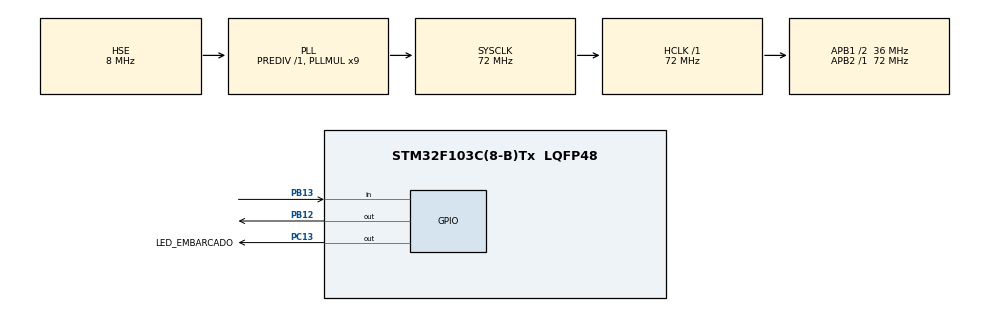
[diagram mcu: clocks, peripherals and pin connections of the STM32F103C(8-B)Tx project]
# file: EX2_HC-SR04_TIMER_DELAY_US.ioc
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Mcu.Family=STM32F1
Mcu.Name=STM32F103C(8-B)Tx
Mcu.Package=LQFP48
NVIC.PriorityGroup=NVIC_PRIORITYGROUP_4
PA13.Mode=Serial_Wire
PA13.Signal=SYS_JTMS-SWDIO
PA14.Mode=Serial_Wire
PA14.Signal=SYS_JTCK-SWCLK
PB12.Signal=GPIO_Output
PB13.Signal=GPIO_Input
PC13-TAMPER-RTC.GPIO_Label=LED_EMBARCADO
PC13-TAMPER-RTC.Signal=GPIO_Output
PD0-OSC_IN.Mode=HSE-External-Oscillator
PD0-OSC_IN.Signal=RCC_OSC_IN
PD1-OSC_OUT.Mode=HSE-External-Oscillator
PD1-OSC_OUT.Signal=RCC_OSC_OUT
ProjectManager.HeapSize=0x200
ProjectManager.StackSize=0x400
ProjectManager.TargetToolchain=STM32CubeIDE
RCC.AHBFreq_Value=72000000
RCC.APB1CLKDivider=RCC_HCLK_DIV2
RCC.APB1Freq_Value=36000000
RCC.APB1TimFreq_Value=72000000
RCC.APB2Freq_Value=72000000
RCC.APB2TimFreq_Value=72000000
RCC.HCLKFreq_Value=72000000
RCC.PLLMUL=RCC_PLL_MUL9
RCC.PLLSourceVirtual=RCC_PLLSOURCE_HSE
RCC.SYSCLKFreq_VALUE=72000000
RCC.SYSCLKSource=RCC_SYSCLKSOURCE_PLLCLK
RCC.USBFreq_Value=72000000
TIM1.Period=0xffff-1
TIM1.Prescaler=72-1
VP_TIM1_VS_ClockSourceINT.Mode=Internal
board=custom

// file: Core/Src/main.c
/* USER CODE BEGIN Header */
/**
  ******************************************************************************
  * @file           : main.c
  * @brief          : Main program body
  ******************************************************************************
  *						 EXEMPLO DE SENSOR ULTRASSOM (stm32f103c8)
  ******************************************************************************
  * Aluno:        Ruan Robert Bispo dos Santos                            2019.2
  * Orientadores: Lucas Molina e Elyson Adan Nunes Carvalho
  *
  * CODIGO DA PLACA DE INTERFACE DO MATLAB COM O STM32F103C8
  *
  * @Resumo: Código teste para sensor ultrassom HC-SR04. Nesse exemplo é
  * 		 implementada uma função delay_us que usa o timer para fazer o delay
  * 		 em micro segundos, assim atuando no sensor ultrassônico.O
  *
  * @Configurações:
  *   		 Clock   - 72 MHz
  *
  * @Funções:
  * 		 void delay_us (uint16_t us)
  * 		 uint32_t hcsr04_read (void)
  *
  *
  ******************************************************************************* @attention
  *
  * <h2><center>&copy; Copyright (c) 2020 STMicroelectronics.
  * All rights reserved.</center></h2>
  *
  * This software component is licensed by ST under BSD 3-Clause license,
  * the "License"; You may not use this file except in compliance with the
  * License. You may obtain a copy of the License at:
  *                        opensource.org/licenses/BSD-3-Clause
  *
  ******************************************************************************
  */
/* USER CODE END Header */

#include "main.h"

/* USER CODE BEGIN PD */

#define Trig_Pin  GPIO_PIN_12       //Pino usado para trigger (definir como pino de saída/gravação)
#define Trig_Port GPIOB			    //Port utilizado no pino de Trigger
#define Echo_Pin  GPIO_PIN_13		//Pino usado para eco (definir como pino de entrada/leitura)
#define Echo_Port GPIOB				//Port utilizado no pino de eco

/* USER CODE END PD */

TIM_HandleTypeDef htim1;

/* USER CODE BEGIN PV */

uint32_t tempo_local;
uint32_t tempo_sensor;
uint32_t distancia;

/* USER CODE END PV */

void SystemClock_Config(void);
static void MX_GPIO_Init(void);
static void MX_TIM1_Init(void);
/* USER CODE BEGIN PFP */

////////////////////////////////////////////////////////
////////////// FUNÇÕES PARA ULTRASSOM //////////////////
////////////////////////////////////////////////////////

// função delay em micro segundos
void delay_us (uint16_t us) // É necessário antes configurar o timer para 1MHz
{
	__HAL_TIM_SET_COUNTER(&htim1,0);  // set o contador como zero
	while (__HAL_TIM_GET_COUNTER(&htim1) < us);  // espera até o contador alcançar o tempo
}

// read ultrassom
uint32_t hcsr04_read (void)
{
	tempo_local=0;
	HAL_GPIO_WritePin(Trig_Port, Trig_Pin, GPIO_PIN_RESET);  // Coloca o trigger em nível alto
	delay_us(2);  											 // Espera 2 us

	HAL_GPIO_WritePin(Trig_Port, Trig_Pin, GPIO_PIN_SET);    // Coloca o trigger em nível alto
	delay_us(10); 											 // Espera 10 us
	HAL_GPIO_WritePin(Trig_Port, Trig_Pin, GPIO_PIN_RESET);  // Coloca o trigger em nível baixo

	// Lê o tempo que o pino passou em alto

	while (!(HAL_GPIO_ReadPin(Echo_Port, Echo_Pin)));  		// Espera o pino de eco ficar em alto
	while (HAL_GPIO_ReadPin(Echo_Port, Echo_Pin)) 		    // Preso enquanto o pino está em alto
	 {
		tempo_local++;   									// Mede o tempo que ficou em alto
		delay_us(1);
	 }
	return tempo_local;										// Retorna o tempo
}

/* USER CODE END PFP */

int main(void)
{
  /* USER CODE BEGIN 1 */

	///////////////////////////////////////////////////////////////////
	/////////////////// INICIALIZAÇÃO DE FUNÇÕES //////////////////////
	///////////////////////////////////////////////////////////////////

	// timer (ultrassom)
	HAL_TIM_Base_Start(&htim1);
	__HAL_TIM_SET_COUNTER(&htim1,0);  // set the counter value a 0

	///////////////////////////////////////////////////////////////////
	///////////////////////////////////////////////////////////////////

  /* USER CODE END 1 */

  /* MCU Configuration--------------------------------------------------------*/

  /* Reset of all peripherals, Initializes the Flash interface and the Systick. */
  HAL_Init();

  /* Configure the system clock */
  SystemClock_Config();

  /* Initialize all configured peripherals */
  MX_GPIO_Init();
  MX_TIM1_Init();

  /* Infinite loop */
  /* USER CODE BEGIN WHILE */
  while (1)
  {

	  // ULTRASSOM *****************************************//
	  	  tempo_sensor = hcsr04_read();    			 // tempo de leitura até o sinal retornar
	  	  distancia  = tempo_sensor * 0.034;			 // usa velocidade do som para calcular a distancia
	  // ***************************************************//

	  // Indicador de que o código está sendo executado (Piscar LED)
		  HAL_GPIO_TogglePin(GPIOC, GPIO_PIN_13); 	 //Pisca led da placa
		  HAL_Delay(500);   						 //Delay em milisegundos

    /* USER CODE END WHILE */

  }
}

void SystemClock_Config(void)
{
  RCC_OscInitTypeDef RCC_OscInitStruct = {0};
  RCC_ClkInitTypeDef RCC_ClkInitStruct = {0};

  /** Initializes the CPU, AHB and APB busses clocks
  */
  RCC_OscInitStruct.OscillatorType = RCC_OSCILLATORTYPE_HSE;
  RCC_OscInitStruct.HSEState = RCC_HSE_ON;
  RCC_OscInitStruct.HSEPredivValue = RCC_HSE_PREDIV_DIV1;
  RCC_OscInitStruct.HSIState = RCC_HSI_ON;
  RCC_OscInitStruct.PLL.PLLState = RCC_PLL_ON;
  RCC_OscInitStruct.PLL.PLLSource = RCC_PLLSOURCE_HSE;
  RCC_OscInitStruct.PLL.PLLMUL = RCC_PLL_MUL9;
  if (HAL_RCC_OscConfig(&RCC_OscInitStruct) != HAL_OK)
  {
    Error_Handler();
  }
  /** Initializes the CPU, AHB and APB busses clocks
  */
  RCC_ClkInitStruct.ClockType = RCC_CLOCKTYPE_HCLK|RCC_CLOCKTYPE_SYSCLK
                              |RCC_CLOCKTYPE_PCLK1|RCC_CLOCKTYPE_PCLK2;
  RCC_ClkInitStruct.SYSCLKSource = RCC_SYSCLKSOURCE_PLLCLK;
  RCC_ClkInitStruct.AHBCLKDivider = RCC_SYSCLK_DIV1;
  RCC_ClkInitStruct.APB1CLKDivider = RCC_HCLK_DIV2;
  RCC_ClkInitStruct.APB2CLKDivider = RCC_HCLK_DIV1;

  if (HAL_RCC_ClockConfig(&RCC_ClkInitStruct, FLASH_LATENCY_2) != HAL_OK)
  {
    Error_Handler();
  }
}

static void MX_TIM1_Init(void)
{

  TIM_ClockConfigTypeDef sClockSourceConfig = {0};
  TIM_MasterConfigTypeDef sMasterConfig = {0};

  htim1.Instance = TIM1;
  htim1.Init.Prescaler = 72-1;
  htim1.Init.CounterMode = TIM_COUNTERMODE_UP;
  htim1.Init.Period = 0xffff-1;
  htim1.Init.ClockDivision = TIM_CLOCKDIVISION_DIV1;
  htim1.Init.RepetitionCounter = 0;
  htim1.Init.AutoReloadPreload = TIM_AUTORELOAD_PRELOAD_DISABLE;
  if (HAL_TIM_Base_Init(&htim1) != HAL_OK)
  {
    Error_Handler();
  }
  sClockSourceConfig.ClockSource = TIM_CLOCKSOURCE_INTERNAL;
  if (HAL_TIM_ConfigClockSource(&htim1, &sClockSourceConfig) != HAL_OK)
  {
    Error_Handler();
  }
  sMasterConfig.MasterOutputTrigger = TIM_TRGO_RESET;
  sMasterConfig.MasterSlaveMode = TIM_MASTERSLAVEMODE_DISABLE;
  if (HAL_TIMEx_MasterConfigSynchronization(&htim1, &sMasterConfig) != HAL_OK)
  {
    Error_Handler();
  }

}

static void MX_GPIO_Init(void)
{
  GPIO_InitTypeDef GPIO_InitStruct = {0};

  /* GPIO Ports Clock Enable */
  __HAL_RCC_GPIOC_CLK_ENABLE();
  __HAL_RCC_GPIOD_CLK_ENABLE();
  __HAL_RCC_GPIOB_CLK_ENABLE();
  __HAL_RCC_GPIOA_CLK_ENABLE();

  /*Configure GPIO pin Output Level */
  HAL_GPIO_WritePin(LED_EMBARCADO_GPIO_Port, LED_EMBARCADO_Pin, GPIO_PIN_RESET);

  /*Configure GPIO pin Output Level */
  HAL_GPIO_WritePin(GPIOB, GPIO_PIN_12, GPIO_PIN_RESET);

  /*Configure GPIO pin : LED_EMBARCADO_Pin */
  GPIO_InitStruct.Pin = LED_EMBARCADO_Pin;
  GPIO_InitStruct.Mode = GPIO_MODE_OUTPUT_PP;
  GPIO_InitStruct.Pull = GPIO_NOPULL;
  GPIO_InitStruct.Speed = GPIO_SPEED_FREQ_LOW;
  HAL_GPIO_Init(LED_EMBARCADO_GPIO_Port, &GPIO_InitStruct);

  /*Configure GPIO pin : PB12 */
  GPIO_InitStruct.Pin = GPIO_PIN_12;
  GPIO_InitStruct.Mode = GPIO_MODE_OUTPUT_PP;
  GPIO_InitStruct.Pull = GPIO_NOPULL;
  GPIO_InitStruct.Speed = GPIO_SPEED_FREQ_LOW;
  HAL_GPIO_Init(GPIOB, &GPIO_InitStruct);

  /*Configure GPIO pin : PB13 */
  GPIO_InitStruct.Pin = GPIO_PIN_13;
  GPIO_InitStruct.Mode = GPIO_MODE_INPUT;
  GPIO_InitStruct.Pull = GPIO_NOPULL;
  HAL_GPIO_Init(GPIOB, &GPIO_InitStruct);

}

void Error_Handler(void)
{
}

/************************ (C) COPYRIGHT STMicroelectronics *****END OF FILE****/
